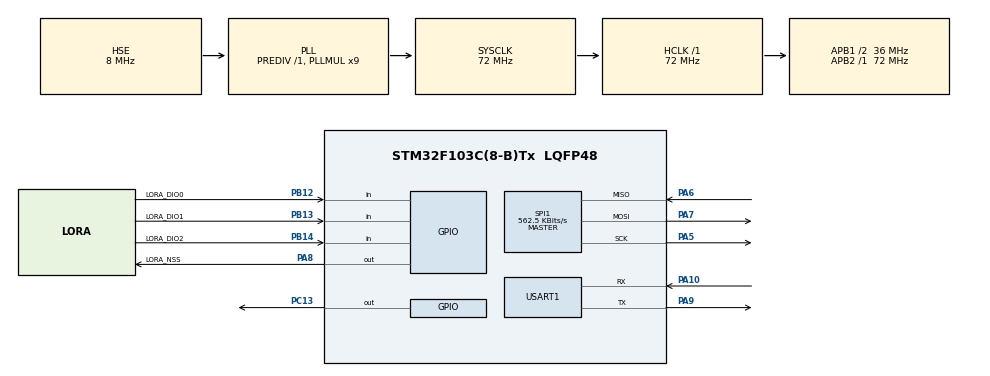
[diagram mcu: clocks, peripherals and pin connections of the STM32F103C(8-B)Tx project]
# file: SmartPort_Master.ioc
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Dma.Request0=USART1_RX
Dma.USART1_RX.0.Direction=DMA_PERIPH_TO_MEMORY
Dma.USART1_RX.0.Instance=DMA1_Channel5
Dma.USART1_RX.0.MemDataAlignment=DMA_MDATAALIGN_BYTE
Dma.USART1_RX.0.MemInc=DMA_MINC_ENABLE
Dma.USART1_RX.0.Mode=DMA_NORMAL
Dma.USART1_RX.0.PeriphDataAlignment=DMA_PDATAALIGN_BYTE
Dma.USART1_RX.0.PeriphInc=DMA_PINC_DISABLE
Dma.USART1_RX.0.Priority=DMA_PRIORITY_LOW
FREERTOS.Tasks01=defaultTask,0,128,StartDefaultTask,Default,NULL
Mcu.Family=STM32F1
Mcu.Name=STM32F103C(8-B)Tx
Mcu.Package=LQFP48
NVIC.DMA1_Channel5_IRQn=true\:5\:0\:false\:false\:true\:true\:false\:true
NVIC.PriorityGroup=NVIC_PRIORITYGROUP_4
NVIC.USART1_IRQn=true\:5\:0\:false\:false\:true\:true\:true\:true
PA10.Mode=Asynchronous
PA10.Signal=USART1_RX
PA13.Mode=Serial_Wire
PA13.Signal=SYS_JTMS-SWDIO
PA14.Mode=Serial_Wire
PA14.Signal=SYS_JTCK-SWCLK
PA5.Mode=Full_Duplex_Master
PA5.Signal=SPI1_SCK
PA6.Mode=Full_Duplex_Master
PA6.Signal=SPI1_MISO
PA7.Mode=Full_Duplex_Master
PA7.Signal=SPI1_MOSI
PA8.GPIO_Label=LORA_NSS
PA8.Signal=GPIO_Output
PA9.Mode=Asynchronous
PA9.Signal=USART1_TX
PB12.GPIO_Label=LORA_DIO0
PB12.Signal=GPIO_Input
PB13.GPIO_Label=LORA_DIO1
PB13.Signal=GPIO_Input
PB14.GPIO_Label=LORA_DIO2
PB14.Signal=GPIO_Input
PC13-TAMPER-RTC.Signal=GPIO_Output
PD0-OSC_IN.Mode=HSE-External-Oscillator
PD0-OSC_IN.Signal=RCC_OSC_IN
PD1-OSC_OUT.Mode=HSE-External-Oscillator
PD1-OSC_OUT.Signal=RCC_OSC_OUT
ProjectManager.HeapSize=0x200
ProjectManager.StackSize=0x400
ProjectManager.TargetToolchain=Makefile
RCC.AHBFreq_Value=72000000
RCC.APB1CLKDivider=RCC_HCLK_DIV2
RCC.APB1Freq_Value=36000000
RCC.APB1TimFreq_Value=72000000
RCC.APB2Freq_Value=72000000
RCC.APB2TimFreq_Value=72000000
RCC.HCLKFreq_Value=72000000
RCC.PLLMUL=RCC_PLL_MUL9
RCC.PLLSourceVirtual=RCC_PLLSOURCE_HSE
RCC.SYSCLKFreq_VALUE=72000000
RCC.SYSCLKSource=RCC_SYSCLKSOURCE_PLLCLK
RCC.USBFreq_Value=72000000
SPI1.BaudRatePrescaler=SPI_BAUDRATEPRESCALER_128
SPI1.CalculateBaudRate=562.5 KBits/s
SPI1.Direction=SPI_DIRECTION_2LINES
SPI1.Mode=SPI_MODE_MASTER
SPI1.VirtualType=VM_MASTER
USART1.VirtualMode=VM_ASYNC
VP_FREERTOS_VS_CMSIS_V1.Mode=CMSIS_V1
board=custom

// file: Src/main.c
/* USER CODE BEGIN Header */
/**
  ******************************************************************************
  * @file           : main.c
  * @brief          : Main program body
  ******************************************************************************
  * @attention
  *
  * <h2><center>&copy; Copyright (c) 2019 STMicroelectronics.
  * All rights reserved.</center></h2>
  *
  * This software component is licensed by ST under BSD 3-Clause license,
  * the "License"; You may not use this file except in compliance with the
  * License. You may obtain a copy of the License at:
  *                        opensource.org/licenses/BSD-3-Clause
  *
  ******************************************************************************
  */
/* USER CODE END Header */

#include "main.h"
#include "cmsis_os.h"
#include "dma.h"
#include "spi.h"
#include "usart.h"
#include "gpio.h"

/* USER CODE BEGIN Includes */
#include "Network_Adapter.h"
/* USER CODE END Includes */

void SystemClock_Config(void);
void MX_FREERTOS_Init(void);

int main(void)
{
  /* USER CODE BEGIN 1 */
  SystemCoreClockUpdate();
  /* USER CODE END 1 */

  /* MCU Configuration--------------------------------------------------------*/

  /* Reset of all peripherals, Initializes the Flash interface and the Systick. */
  HAL_Init();

  /* Configure the system clock */
  SystemClock_Config();

  /* Initialize all configured peripherals */
  MX_GPIO_Init();
  MX_DMA_Init();
  MX_USART1_UART_Init();
  MX_SPI1_Init();

  /* Call init function for freertos objects (in freertos.c) */
  MX_FREERTOS_Init();

  /* Start scheduler */
  osKernelStart();

  /* We should never get here as control is now taken by the scheduler */

  /* Infinite loop */
  while (1)
  {

  }
}

void SystemClock_Config(void)
{
  RCC_OscInitTypeDef RCC_OscInitStruct = {0};
  RCC_ClkInitTypeDef RCC_ClkInitStruct = {0};

  /** Initializes the CPU, AHB and APB busses clocks
  */
  RCC_OscInitStruct.OscillatorType = RCC_OSCILLATORTYPE_HSE;
  RCC_OscInitStruct.HSEState = RCC_HSE_ON;
  RCC_OscInitStruct.HSEPredivValue = RCC_HSE_PREDIV_DIV1;
  RCC_OscInitStruct.HSIState = RCC_HSI_ON;
  RCC_OscInitStruct.PLL.PLLState = RCC_PLL_ON;
  RCC_OscInitStruct.PLL.PLLSource = RCC_PLLSOURCE_HSE;
  RCC_OscInitStruct.PLL.PLLMUL = RCC_PLL_MUL9;
  if (HAL_RCC_OscConfig(&RCC_OscInitStruct) != HAL_OK)
  {
    Error_Handler();
  }
  /** Initializes the CPU, AHB and APB busses clocks
  */
  RCC_ClkInitStruct.ClockType = RCC_CLOCKTYPE_HCLK|RCC_CLOCKTYPE_SYSCLK
                              |RCC_CLOCKTYPE_PCLK1|RCC_CLOCKTYPE_PCLK2;
  RCC_ClkInitStruct.SYSCLKSource = RCC_SYSCLKSOURCE_PLLCLK;
  RCC_ClkInitStruct.AHBCLKDivider = RCC_SYSCLK_DIV1;
  RCC_ClkInitStruct.APB1CLKDivider = RCC_HCLK_DIV2;
  RCC_ClkInitStruct.APB2CLKDivider = RCC_HCLK_DIV1;

  if (HAL_RCC_ClockConfig(&RCC_ClkInitStruct, FLASH_LATENCY_2) != HAL_OK)
  {
    Error_Handler();
  }
}

void Error_Handler(void)
{
}

/************************ (C) COPYRIGHT STMicroelectronics *****END OF FILE****/

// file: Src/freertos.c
/* USER CODE BEGIN Header */
/**
  ******************************************************************************
  * File Name          : freertos.c
  * Description        : Code for freertos applications
  ******************************************************************************
  * @attention
  *
  * <h2><center>&copy; Copyright (c) 2019 STMicroelectronics.
  * All rights reserved.</center></h2>
  *
  * This software component is licensed by ST under Ultimate Liberty license
  * SLA0044, the "License"; You may not use this file except in compliance with
  * the License. You may obtain a copy of the License at:
  *                             www.st.com/SLA0044
  *
  ******************************************************************************
  */
/* USER CODE END Header */

#include "FreeRTOS.h"
#include "task.h"
#include "main.h"
#include "cmsis_os.h"

/* USER CODE BEGIN Includes */
#include "SmartPart.h"
/* USER CODE END Includes */

osThreadId defaultTaskHandle;

void StartDefaultTask(void const * argument);

void MX_FREERTOS_Init(void); /* (MISRA C 2004 rule 8.1) */

void MX_FREERTOS_Init(void) {

  /* Create the thread(s) */
  /* definition and creation of defaultTask */
  osThreadDef(defaultTask, StartDefaultTask, osPriorityNormal, 0, 128);
  defaultTaskHandle = osThreadCreate(osThread(defaultTask), NULL);

  /* USER CODE BEGIN RTOS_THREADS */
  /* add threads, ... */
  xTaskCreate(SmartPart_Task,"SmartPart_Task",128,NULL,8,NULL);
  /* USER CODE END RTOS_THREADS */

}

void StartDefaultTask(void const * argument)
{

  for(;;)
  {
    osDelay(1);
  }
}

/************************ (C) COPYRIGHT STMicroelectronics *****END OF FILE****/
